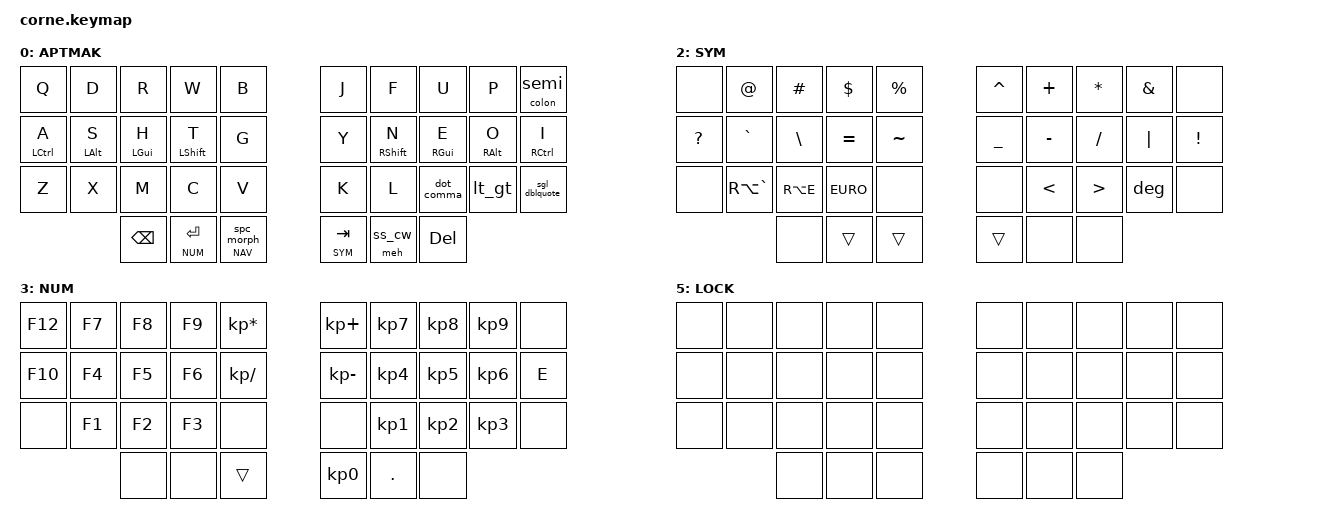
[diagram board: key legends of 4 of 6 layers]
/*
 * Copyright (c) 2020 The ZMK Contributors
 *
 * SPDX-License-Identifier: MIT
 */

#include <behaviors.dtsi>
#include <dt-bindings/zmk/keys.h>
#include <dt-bindings/zmk/bt.h>

#define BASE 0
#define NAV 1
#define SYM 2
#define NUM 3
#define ADJ 4
#define LOCKL 5

#define ___ &none

// 36 keys physical layout
#define LEFT_KEYS 0 1 2 3 4 10 11 12 13 14 20 21 22 23 24 // left-hand keys
#define RIGHT_KEYS 5 6 7 8 9 15 16 17 18 19 25 26 27 28 29 // right-hand keys
#define THUMBS 30 31 32 33 34 35 // thumb keys

// macros definition
#define meh LG(LC(LALT))
#define hyper LG(LC(LS(LALT)))
#define deg RA(LS(N8))
#define HR_APP LG(LS(SPACE))

// tune mod tap
&mt {
    flavor = "tap-preferred";
    tapping_term_ms = <200>;
};

// layer tap config
&lt {
    flavor = "balanced";
    tapping-term-ms = <TAP_TERM_MS>;
    quick-tap-ms = <QUICK_TAP_MS>;      // double-tap + hold repeats tap-key
};

// tune sticky key
&sk {
    release-after-ms = <1000>;
    quick-release;
};

// sticky layer config
&sl {
    release-after-ms = <700>;
};

// caps word settings
&caps_word {
    continue-list = <UNDERSCORE MINUS BSPC N1 N2 N3 N4 N5 N6 N7 N8 N9 N0>;
};

/ {

		behaviors {
        // HOME ROW MODS
        hml: left_hand_positional_hold_tap {
            compatible = "zmk,behavior-hold-tap";
            label = "LEFT_POSITIONAL_HOLD_TAP";
            #binding-cells = <2>;
            flavor = "balanced";
            tapping-term-ms = <TAP_TERM_MS>;
            quick-tap-ms = <QUICK_TAP_MS>;       // double-tap + hold repeats tap-key
            require-prior-idle-ms = <150>;       // do not activate HOLD during typing flow
            bindings = <&kp>, <&kp>;
            hold-trigger-key-positions = <RIGHT_KEYS THUMBS>;
            hold-trigger-on-release;
        };

        hmr: right_hand_positional_hold_tap {
            compatible = "zmk,behavior-hold-tap";
            label = "RIGHT_POSITIONAL_HOLD_TAP";
            #binding-cells = <2>;
            flavor = "balanced";
            tapping-term-ms = <TAP_TERM_MS>;
            quick-tap-ms = <QUICK_TAP_MS>;       // double-tap + hold repeats tap-key
            require-prior-idle-ms = <150>;       // do not activate HOLD during typing flow
            bindings = <&kp>, <&kp>;
            hold-trigger-key-positions = <LEFT_KEYS THUMBS>;
            hold-trigger-on-release;
        };
				// tap: sticky-shift | lshft + tap: caps-word | hold: set in keymap (HYPER)
        ss_cw: ss_cw {
            compatible = "zmk,behavior-mod-morph";
            label = "SS_CW";
            #binding-cells = <0>;
            bindings = <&sk LSHFT>, <&caps_word>;
            mods = <(MOD_LSFT|MOD_RSFT)>;
        };
        lt_shft: lt_shft {
            compatible = "zmk,behavior-hold-tap";
            label = "LT_SHFT";
            #binding-cells = <2>;
            tapping-term-ms = <TAP_TERM_MS>;
            quick-tap-ms = <QUICK_TAP_MS>;
            flavor = "balanced";
            bindings = <&kp>, <&ss_cw>;
        };

        // tap: space | shft + tap: dot -> space -> sticky shift | hold: activate layer
        spc_morph: spc_morph {
            compatible = "zmk,behavior-mod-morph";
            label = "SPC_MORPH";
            #binding-cells = <0>;
            bindings = <&kp SPACE>, <&dot_spc>;
            mods = <(MOD_LSFT)>;
        };
        lt_spc: lt_spc {
            compatible = "zmk,behavior-hold-tap";
            label = "LT_SPC";
            #binding-cells = <2>;
            tapping-term-ms = <TAP_TERM_MS>;
            quick-tap-ms = <QUICK_TAP_MS>;
            flavor = "balanced";
            bindings = <&mo>, <&spc_morph>;
        };
        colon_semi: colon_semi {
            compatible = "zmk,behavior-mod-morph";
            label = "COLON_TO_SEMICOLON";
            #binding-cells = <0>;
            bindings = <&kp COLON>, <&kp SEMICOLON>;
            mods = <(MOD_LSFT|MOD_RSFT)>;
        };
        dot_comma: dot_comma {
            compatible = "zmk,behavior-mod-morph";
            label = "DOT_TO_COMMA";
            #binding-cells = <0>;
            bindings = <&kp DOT>, <&kp COMMA>;
            mods = <(MOD_LSFT|MOD_RSFT)>;
        };
        lt_gt: lt_gt {
            compatible = "zmk,behavior-mod-morph";
            label = "LESSTHAN_TO_GREATERTHAN";
            #binding-cells = <0>;
            bindings = <&kp LT>, <&kp GT>;
            mods = <(MOD_LSFT|MOD_RSFT)>;
        };
        quest_excl: quest_excl {
            compatible = "zmk,behavior-mod-morph";
            label = "quest_to_excl";
            #binding-cells = <0>;
            bindings = <&kp QUESTION>, <&kp EXCLAMATION>;
            mods = <(MOD_LSFT|MOD_RSFT)>;
        };
        sgl_dblqutoe: sgl_dblqutoe {
            compatible = "zmk,behavior-mod-morph";
            label = "SINGLE_TO_DOUBLEQUOTE";
            #binding-cells = <0>;
            bindings = <&kp SINGLE_QUOTE>, <&kp DOUBLE_QUOTES>;
            mods = <(MOD_LSFT|MOD_RSFT)>;
        };
		};

    conditional_layers {
        compatible = "zmk,conditional-layers";
        tri_layer {
            if-layers = <NAV SYM>;
            then-layer = <ADJ>;
        };
    };

    macros {
        sel_word: select_word {
            label = "ZM_SELECT_WORD";
            compatible = "zmk,behavior-macro";
            #binding-cells = <0>;
            bindings
                = <&macro_press &kp LCTRL>
                , <&macro_tap &kp LEFT>
                , <&macro_press &kp LSHFT>
                , <&macro_tap &kp RIGHT>
                , <&macro_release &kp LSHFT &kp LCTRL>
                ;
        };

        dot_spc: dot_spc{
            label = "ZM_DOT_SPACE";
            compatible = "zmk,behavior-macro";
            #binding-cells = <0>;
            wait-ms = <0>;
            tap-ms = <5>;
            bindings = <&kp DOT &kp SPACE &sk LSHFT>;
        };
	};

    keymap {
        compatible = "zmk,keymap";

        default_layer {
            label = "APTMAK";
            bindings = <
             //╭──────────────┬──────────────┬──────────────┬──────────────┬──────────────╮     ╭──────────────┬──────────────┬──────────────┬──────────────┬──────────────╮
                &kp Q          &kp D          &kp R          &kp W          &kp B                &kp J          &kp F          &kp U          &kp P          &colon semi
             //├──────────────┼──────────────┼──────────────┼──────────────┼──────────────┤     ├──────────────┼──────────────┼──────────────┼──────────────┼──────────────┤
                &hml LCTRL A   &hml LALT S    &hml LGUI   H  &hml LSHIFT T  &kp G                &kp Y          &hmr RSHIFT N  &hmr RGUI E    &hmr RALT O    &hmr RCTRL I
             //├──────────────┼──────────────┼──────────────┼──────────────┼──────────────┤     ├──────────────┼──────────────┼──────────────┼──────────────┼──────────────┤
                &kp Z          &kp X          &kp M          &kp C          &kp V                &kp K          &kp L          &dot_comma     &lt_gt         &sgl_dblquote
             //╰──────────────┴──────────────┼──────────────┼──────────────┼──────────────┤     ├──────────────┼──────────────┼──────────────┼──────────────┴──────────────╯
                                              &kp BSPC       &lt NUM RET    &lt_spc NAV 0        &lt SYM TAB    &lt_shft meh 0 &kp DEL
             //                              ╰──────────────┴──────────────┴──────────────╯     ╰──────────────┴──────────────┴──────────────╯
            >;
        };

        nav_layer{
            label = "NAV";
            bindings = <
             //╭──────────────┬──────────────┬──────────────┬──────────────┬──────────────╮     ╭──────────────┬──────────────┬──────────────┬──────────────┬──────────────╮
                ___            ___            &kp LG(Q)      &kp LG(W)      ___                  ___            &kp PG_DN      &kp UP         &kp PG_UP      ___
             //├──────────────┼──────────────┼──────────────┼──────────────┼──────────────┤     ├──────────────┼──────────────┼──────────────┼──────────────┼──────────────┤
                &sk LCTRL      &sk LALT       &sk LGUI       &sk LSHIFT     ___                  &kp LA(DEL)    &kp LEFT       &kp DOWN       &kp RIGHT      &kp LC(LG(Q))
             //├──────────────┼──────────────┼──────────────┼──────────────┼──────────────┤     ├──────────────┼──────────────┼──────────────┼──────────────┼──────────────┤
                ___                           ___            &kp LC(TAB)    ___                  ___            &kp DSK_PREV   &kp HR_APP     &kp DSK_NEXT   ___
             //╰──────────────┴──────────────┼──────────────┼──────────────┼──────────────┤     ├──────────────┼──────────────┼──────────────┼──────────────┴──────────────╯
                                              ___            ___            &trans               &trans         ___            ___
             //                              ╰──────────────┴──────────────┴──────────────╯     ╰──────────────┴──────────────┴──────────────╯
            >;
        };

        symbols {
            label = "SYM";
            bindings = <
             //╭──────────────┬──────────────┬──────────────┬──────────────┬──────────────╮     ╭──────────────┬──────────────┬──────────────┬──────────────┬──────────────╮
                ___            &kp AT         &kp HASH       &kp DOLLAR     &kp PERCENT          &kp CARET      &kp PLUS       &kp ASTRK      &kp AMPS       ___
             //├──────────────┼──────────────┼──────────────┼──────────────┼──────────────┤     ├──────────────┼──────────────┼──────────────┼──────────────┼──────────────┤
                &kp QUESTION   &kp GRAVE      &kp BSLH       &kp EQUAL      &kp TILDE            &kp UNDER      &kp MINUS      &kp SLASH      &kp PIPE       &kp EXCL
             //├──────────────┼──────────────┼──────────────┼──────────────┼──────────────┤     ├──────────────┼──────────────┼──────────────┼──────────────┼──────────────┤
                ___            &kp RA(GRAVE)  &kp RA(E)      &kp EURO       ___                  ___            &kp LT         &kp GT         &kp deg        ___
             //╰──────────────┴──────────────┼──────────────┼──────────────┼──────────────┤     ├──────────────┼──────────────┼──────────────┼──────────────┴──────────────╯
                                              ___            &trans         &trans               &trans         ___            ___
             //                              ╰──────────────┴──────────────┴──────────────╯     ╰──────────────┴──────────────┴──────────────╯
            >;
        };

        num_layer{
            label = "NUM";
            bindings = <
             //╭──────────────┬──────────────┬──────────────┬──────────────┬──────────────╮     ╭──────────────┬──────────────┬──────────────┬──────────────┬──────────────╮
                &kp F12        &kp F7         &kp F8         &kp F9         &kp KP_MULTIPLY      &kp KP_PLUS    &kp KP_N7      &kp KP_N8      &kp KP_N9      ___
             //├──────────────┼──────────────┼──────────────┼──────────────┼──────────────┤     ├──────────────┼──────────────┼──────────────┼──────────────┼──────────────┤
                &kp F10        &kp F4         &kp F5         &kp F6         &kp KP_DIVIDE        &kp KP_MINUS   &kp KP_N4      &kp KP_N5      &kp KP_N6      &kp E
             //├──────────────┼──────────────┼──────────────┼──────────────┼──────────────┤     ├──────────────┼──────────────┼──────────────┼──────────────┼──────────────┤
                ___            &kp F1         &kp F2         &kp F3         ___                  ___            &kp KP_N1      &kp KP_N2      &kp KP_N3      ___
             //╰──────────────┴──────────────┼──────────────┼──────────────┼──────────────┤     ├──────────────┼──────────────┼──────────────┼──────────────┴──────────────╯
                                              ___            ___            &trans               &kp KP_N0      &kp DOT        ___
             //                              ╰──────────────┴──────────────┴──────────────╯     ╰──────────────┴──────────────┴──────────────╯
            >;
        };

        adj_layer {
            label = "ADJ";
            bindings = <
             //╭──────────────┬──────────────┬──────────────┬──────────────┬──────────────╮     ╭──────────────┬──────────────┬──────────────┬──────────────┬──────────────╮
                ___            ___            &to 0          &to BASE       &bootloader          &bootloader    &kp C_NEXT     &kp C_PP       &kp C_PREV     ___
             //├──────────────┼──────────────┼──────────────┼──────────────┼──────────────┤     ├──────────────┼──────────────┼──────────────┼──────────────┼──────────────┤
                BTL1                                                        &sys_reset           &sys_reset     &kp C_VOL_DN   &kp C_VOL_UP   &kp C_MUTE     ___
             //├──────────────┼──────────────┼──────────────┼──────────────┼──────────────┤     ├──────────────┼──────────────┼──────────────┼──────────────┼──────────────┤
                BTL2                                                        ___                  ___            &kp C_BRI_DN   &kp C_BRI_UP   ___            ___
             //╰──────────────┴──────────────┼──────────────┼──────────────┼──────────────┤     ├──────────────┼──────────────┼──────────────┼──────────────┴──────────────╯
                                              ___            ___            ___                  ___            ___            ___
             //                              ╰──────────────┴──────────────┴──────────────╯     ╰──────────────┴──────────────┴──────────────╯
            >;
        };

        lock_layer {
            label = "LOCK";
            bindings = <
             //╭──────────────┬──────────────┬──────────────┬──────────────┬──────────────╮     ╭──────────────┬──────────────┬──────────────┬──────────────┬──────────────╮
                ___            ___            ___            ___            ___                  ___            ___            ___            ___            ___
             //├──────────────┼──────────────┼──────────────┼──────────────┼──────────────┤     ├──────────────┼──────────────┼──────────────┼──────────────┼──────────────┤
                ___            ___            ___            ___            ___                  ___            ___            ___            ___            ___
             //├──────────────┼──────────────┼──────────────┼──────────────┼──────────────┤     ├──────────────┼──────────────┼──────────────┼──────────────┼──────────────┤
                ___            ___            ___            ___            ___                  ___            ___            ___            ___            ___
             //╰──────────────┴──────────────┼──────────────┼──────────────┼──────────────┤     ├──────────────┼──────────────┼──────────────┼──────────────┴──────────────╯
                                              ___            ___            ___                  ___            ___            ___
             //                              ╰──────────────┴──────────────┴──────────────╯     ╰──────────────┴──────────────┴──────────────╯
            >;
        };

    };


};
